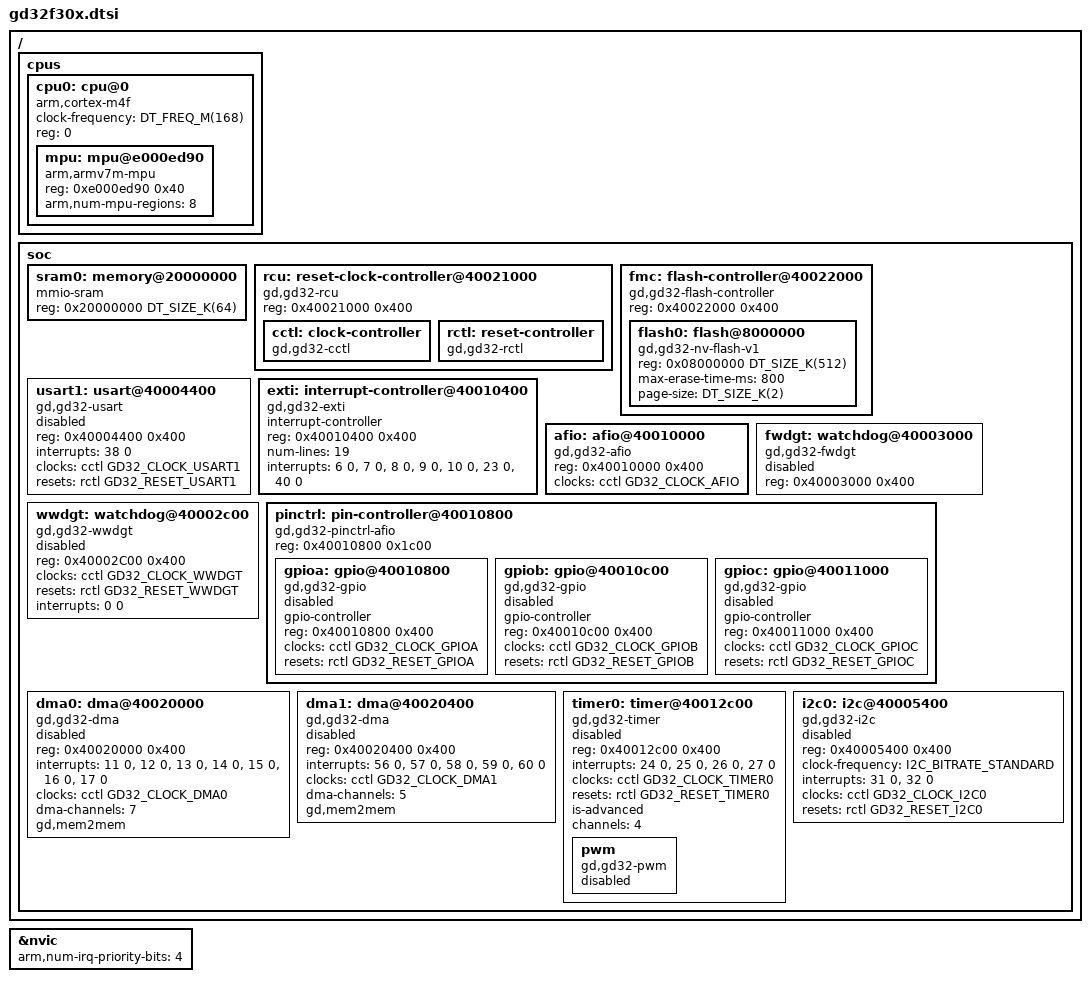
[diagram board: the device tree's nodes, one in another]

#include <mem.h>
#include <freq.h>
#include <arm/armv7-m.dtsi>
#include <zephyr/dt-bindings/gpio/gpio.h>
#include <zephyr/dt-bindings/i2c/i2c.h>
#include <zephyr/dt-bindings/pwm/pwm.h>
#include <zephyr/dt-bindings/clock/gd32f30x-clocks.h>
#include <zephyr/dt-bindings/reset/gd32f30x.h>

/ {
	cpus {
		#address-cells = <1>;
		#size-cells = <0>;

		cpu0: cpu@0 {
			compatible = "arm,cortex-m4f";
			clock-frequency = <DT_FREQ_M(168)>;
			reg = <0>;
			#address-cells = <1>;
			#size-cells = <1>;

			mpu: mpu@e000ed90 {
				compatible = "arm,armv7m-mpu";
				reg = <0xe000ed90 0x40>;
				arm,num-mpu-regions = <8>;
			};
		};
	};

	soc {
		sram0: memory@20000000 {
			compatible = "mmio-sram";
            reg = <0x20000000 DT_SIZE_K(64)>;
		};

        /*No driver compat so omit manual address checking */
		rcu: reset-clock-controller@40021000 {
			compatible = "gd,gd32-rcu";
			reg = <0x40021000 0x400>;
			status = "okay";

			cctl: clock-controller {
				compatible = "gd,gd32-cctl";
				#clock-cells = <1>;
				status = "okay";
			};

			rctl: reset-controller {
				compatible = "gd,gd32-rctl";
				#reset-cells = <1>;
				status = "okay";
			};
		};

		fmc: flash-controller@40022000 {
			compatible = "gd,gd32-flash-controller";
			reg = <0x40022000 0x400>;
			#address-cells = <1>;
			#size-cells = <1>;

			flash0: flash@8000000 {
				reg = <0x08000000 DT_SIZE_K(512)>;
				compatible = "gd,gd32-nv-flash-v1", "soc-nv-flash";
				max-erase-time-ms = <800>;
				page-size = <DT_SIZE_K(2)>;
			};
		};

		usart1: usart@40004400 {
			compatible = "gd,gd32-usart";
			reg = <0x40004400 0x400>;
			interrupts = <38 0>;
			clocks = <&cctl GD32_CLOCK_USART1>;
			resets = <&rctl GD32_RESET_USART1>;
			status = "disabled";
		};

		exti: interrupt-controller@40010400 {
			compatible = "gd,gd32-exti";
			interrupt-controller;
			#interrupt-cells = <1>;
			reg = <0x40010400 0x400>;
			num-lines = <19>;
			interrupts = <6 0>, <7 0>, <8 0>, <9 0>, <10 0>, <23 0>,
				     <40 0>;
			interrupt-names = "line0", "line1", "line2",
					  "line3", "line4", "line5-9",
					  "line10-15";
			status = "okay";
		};

		afio: afio@40010000 {
			compatible = "gd,gd32-afio";
			reg = <0x40010000 0x400>;
			clocks = <&cctl GD32_CLOCK_AFIO>;
			status = "okay";
		};

		fwdgt: watchdog@40003000 {
			compatible = "gd,gd32-fwdgt";
			reg = <0x40003000 0x400>;
			status = "disabled";
		};

		wwdgt: watchdog@40002c00 {
			compatible = "gd,gd32-wwdgt";
			reg = <0x40002C00 0x400>;
			clocks = <&cctl GD32_CLOCK_WWDGT>;
			resets = <&rctl GD32_RESET_WWDGT>;
			interrupts = <0 0>;
			status = "disabled";
		};

		pinctrl: pin-controller@40010800 {
			compatible = "gd,gd32-pinctrl-afio";
			reg = <0x40010800 0x1c00>;
			#address-cells = <1>;
			#size-cells = <1>;
			status = "okay";

			gpioa: gpio@40010800 {
				compatible = "gd,gd32-gpio";
				gpio-controller;
				#gpio-cells = <2>;
				reg = <0x40010800 0x400>;
				clocks = <&cctl GD32_CLOCK_GPIOA>;
				resets = <&rctl GD32_RESET_GPIOA>;
				status = "disabled";
			};

			gpiob: gpio@40010c00 {
				compatible = "gd,gd32-gpio";
				gpio-controller;
				#gpio-cells = <2>;
				reg = <0x40010c00 0x400>;
				clocks = <&cctl GD32_CLOCK_GPIOB>;
				resets = <&rctl GD32_RESET_GPIOB>;
				status = "disabled";
			};

			gpioc: gpio@40011000 {
				compatible = "gd,gd32-gpio";
				gpio-controller;
				#gpio-cells = <2>;
				reg = <0x40011000 0x400>;
				clocks = <&cctl GD32_CLOCK_GPIOC>;
				resets = <&rctl GD32_RESET_GPIOC>;
				status = "disabled";
			};		
		};

		dma0: dma@40020000 {
			compatible = "gd,gd32-dma";
			reg = <0x40020000 0x400>;
			interrupts = <11 0>, <12 0>, <13 0>, <14 0>,
				     <15 0>, <16 0>, <17 0>;
			clocks = <&cctl GD32_CLOCK_DMA0>;
			dma-channels = <7>;
			gd,mem2mem;
			#dma-cells = <2>;
			status = "disabled";
		};

		dma1: dma@40020400 {
			compatible = "gd,gd32-dma";
			reg = <0x40020400 0x400>;
			interrupts = <56 0>, <57 0>, <58 0>, <59 0>,
				     <60 0>;
			clocks = <&cctl GD32_CLOCK_DMA1>;
			dma-channels = <5>;
			gd,mem2mem;
			#dma-cells = <2>;
			status = "disabled";
		};
		
		timer0: timer@40012c00 {
			compatible = "gd,gd32-timer";
			reg = <0x40012c00 0x400>;
			interrupts = <24 0>, <25 0>, <26 0>, <27 0>;
			interrupt-names = "brk", "up", "trgcom", "cc";
			clocks = <&cctl GD32_CLOCK_TIMER0>;
			resets = <&rctl GD32_RESET_TIMER0>;
			is-advanced;
			channels = <4>;
			status = "disabled";

			pwm {
				compatible = "gd,gd32-pwm";
				status = "disabled";
				#pwm-cells = <3>;
			};
		};

		i2c0: i2c@40005400 {
			compatible = "gd,gd32-i2c";
			reg = <0x40005400 0x400>;
			#address-cells = <1>;
			#size-cells = <0>;
			clock-frequency = <I2C_BITRATE_STANDARD>;
			interrupts = <31 0>, <32 0>;
			interrupt-names = "event", "error";
			clocks = <&cctl GD32_CLOCK_I2C0>;
			resets = <&rctl GD32_RESET_I2C0>;
			status = "disabled";
		};

	};
};

&nvic {
	arm,num-irq-priority-bits = <4>;
};
